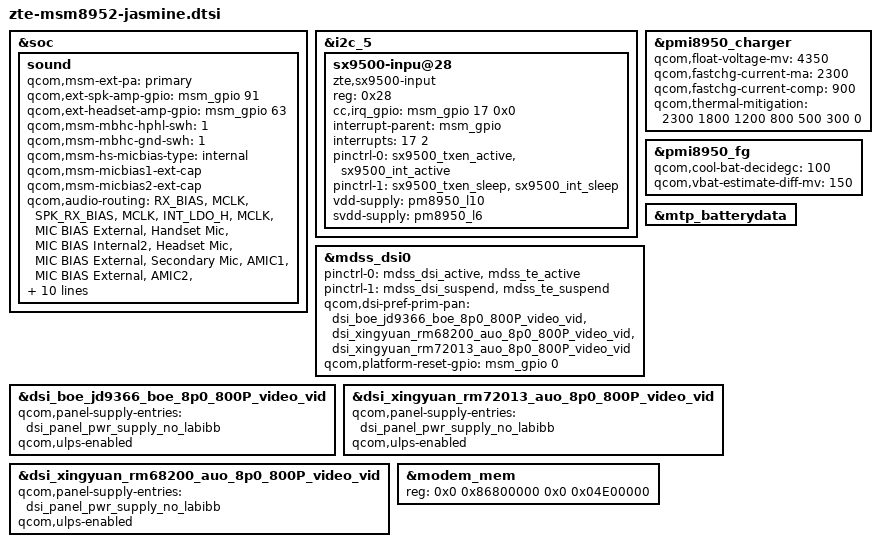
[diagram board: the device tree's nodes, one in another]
/*
 * device tree for zte jasmine board
 */

#include "touch-key-backlight-jasmine.dtsi"
#include "zte-msm8952-jasmine-camera.dtsi"

#include "dsi-panel-zte-boe-jd9366-boe-8p0-800p-video.dtsi"
#include "dsi-panel-zte-xingyuan-rm72013-auo-8p0-800p-video.dtsi"
#include "dsi-panel-zte-xingyuan-rm68200-auo-8p0-800p-video.dtsi"
&soc {
	 sound {
		qcom,msm-ext-pa = "primary";
		qcom,ext-spk-amp-gpio = <&msm_gpio 91 0>;
		qcom,ext-headset-amp-gpio = <&msm_gpio 63 0>;
		qcom,msm-mbhc-hphl-swh = <1>;
		qcom,msm-mbhc-gnd-swh = <1>;
		qcom,msm-hs-micbias-type = "internal";
		qcom,msm-micbias1-ext-cap;
		qcom,msm-micbias2-ext-cap;
		qcom,audio-routing =
			"RX_BIAS", "MCLK",
			"SPK_RX_BIAS", "MCLK",
			"INT_LDO_H", "MCLK",
			"MIC BIAS External", "Handset Mic",
			"MIC BIAS Internal2", "Headset Mic",
			"MIC BIAS External", "Secondary Mic",
			"AMIC1", "MIC BIAS External",
			"AMIC2", "MIC BIAS Internal2",
			"AMIC3", "MIC BIAS External",
			"Lineout_hph amp", "HEADPHONE",
			"WSA_SPK OUT", "VDD_WSA_SWITCH",
			"SpkrMono WSA_IN", "WSA_SPK OUT";
		qcom,msm-gpios =
			"pri_i2s";
		qcom,pinctrl-names =
			"all_off",
			"pri_i2s_act";
		pinctrl-names =
			"all_off",
			"pri_i2s_act";
		pinctrl-0 = <&cdc_pdm_lines_sus &cdc_pdm_lines_2_sus >;
		pinctrl-1 = <&cdc_pdm_lines_act &cdc_pdm_lines_2_act >;
	};
};

&i2c_5 { /* BLSP2 QUP1 */
	sx9500-inpu@28 {
		compatible = "zte,sx9500-input";
		reg = <0x28>;
		cc,irq_gpio = <&msm_gpio 17 0x0>;
		interrupt-parent = <&msm_gpio>;
		interrupts = <17 2>;
		interrupt-names = "sx9500_irq";
		pinctrl-names = "sx9500_active", "sx9500_sleep";
		pinctrl-0 = <&sx9500_txen_active &sx9500_int_active>;
		pinctrl-1 = <&sx9500_txen_sleep &sx9500_int_sleep >;
		vdd-supply = <&pm8950_l10>;
		svdd-supply = <&pm8950_l6>;
	};
};

&pmi8950_charger {
	qcom,float-voltage-mv = <4350>;
	qcom,fastchg-current-ma = <2300>;
	qcom,fastchg-current-comp = <900>;
	qcom,thermal-mitigation = <2300 1800 1200 800 500 300 0>;
};

&pmi8950_fg{
	qcom,cool-bat-decidegc = <100>;
	qcom,vbat-estimate-diff-mv = <150>;
};

&mtp_batterydata {
		#include "ZTE_P895A80_4620mAh_sony.dtsi"
		#include "ZTE_P895A80_4620mAh_ATL.dtsi"
};
&mdss_dsi0 {
	pinctrl-names = "mdss_default", "mdss_sleep";
	pinctrl-0 = <&mdss_dsi_active &mdss_te_active>;
	pinctrl-1 = <&mdss_dsi_suspend &mdss_te_suspend>;
	qcom,dsi-pref-prim-pan = <&dsi_boe_jd9366_boe_8p0_800P_video_vid &dsi_xingyuan_rm68200_auo_8p0_800P_video_vid
		 &dsi_xingyuan_rm72013_auo_8p0_800P_video_vid>;
	qcom,platform-reset-gpio = <&msm_gpio 0 0>;
};

&dsi_boe_jd9366_boe_8p0_800P_video_vid {
	qcom,panel-supply-entries = <&dsi_panel_pwr_supply_no_labibb>;
	qcom,ulps-enabled;
};

&dsi_xingyuan_rm72013_auo_8p0_800P_video_vid {
	qcom,panel-supply-entries = <&dsi_panel_pwr_supply_no_labibb>;
	qcom,ulps-enabled;
};

&dsi_xingyuan_rm68200_auo_8p0_800P_video_vid {
	qcom,panel-supply-entries = <&dsi_panel_pwr_supply_no_labibb>;
	qcom,ulps-enabled;
};

&modem_mem {
	reg = <0x0 0x86800000 0x0 0x04E00000>;
};

